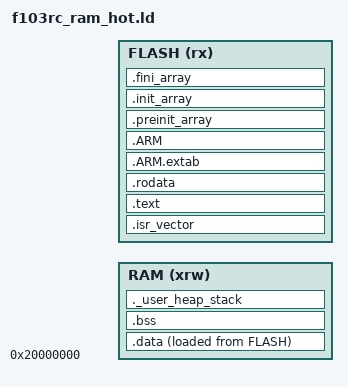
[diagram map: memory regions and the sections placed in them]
/* foc-testbench: copy of the STM32 core 2.12 F103R(C-D-E)T ldscript.ld with the libgcc soft float routines and the SimpleFOC control loop files in RAM (.data). */
/**
 ******************************************************************************
 * @file      LinkerScript.ld
 * @author    Auto-generated by STM32CubeIDE
 * @brief     Linker script for STM32F103C4Tx Device from STM32F1 series
 *                      16Kbytes FLASH
 *                      6Kbytes RAM
 *
 *            Set heap size, stack size and stack location according
 *            to application requirements.
 *
 *            Set memory bank area and size if external memory is used
 ******************************************************************************
 * @attention
 *
 * <h2><center>&copy; Copyright (c) 2020 STMicroelectronics.
 * All rights reserved.</center></h2>
 *
 * This software component is licensed by ST under BSD 3-Clause license,
 * the "License"; You may not use this file except in compliance with the
 * License. You may obtain a copy of the License at:
 *                        opensource.org/licenses/BSD-3-Clause
 *
 ******************************************************************************
 */

/* Entry Point */
ENTRY(Reset_Handler)

/* Highest address of the user mode stack */
_estack = ORIGIN(RAM) + LENGTH(RAM);	/* end of "RAM" Ram type memory */

_Min_Heap_Size = 0x200;	/* required amount of heap  */
_Min_Stack_Size = 0x400;	/* required amount of stack */

/* Memories definition */
MEMORY
{
  RAM    (xrw)    : ORIGIN = 0x20000000,   LENGTH = LD_MAX_DATA_SIZE
  FLASH    (rx)    : ORIGIN = 0x8000000 + LD_FLASH_OFFSET, LENGTH = LD_MAX_SIZE - LD_FLASH_OFFSET
}

/* Sections */
SECTIONS
{
  /* The startup code into "FLASH" Rom type memory */
  .isr_vector :
  {
    . = ALIGN(4);
    KEEP(*(.isr_vector)) /* Startup code */
    . = ALIGN(4);
  } >FLASH

  /* The program code and other data into "FLASH" Rom type memory */
  .text :
  {
    . = ALIGN(4);
    EXCLUDE_FILE(*libgcc.a:_arm_addsubsf3.o *libgcc.a:_arm_mulsf3.o *libgcc.a:_arm_muldivsf3.o *libgcc.a:_arm_cmpsf2.o *libgcc.a:_arm_fixsfsi.o *libgcc.a:_arm_fixunssfsi.o *libgcc.a:_arm_unordsf2.o *FOCMotor.cpp.o *BLDCMotor.cpp.o *pid.cpp.o *lowpass_filter.cpp.o *foc_utils.cpp.o *LowsideCurrentSense.cpp.o *CurrentSense.cpp.o *Sensor.cpp.o *HallSensor.cpp.o *SmoothingSensor.cpp.o *BLDCDriver6PWM.cpp.o *stm32_mcu.cpp.o *stm32f1_mcu.cpp.o *stm32_timerutils.cpp.o *stm32_adc_utils.cpp.o *libm.a:libm_a-ef_fmod.o *libm.a:libm_a-wf_fmod.o) *(.text .text*)   /* code, except the RAM functions below */
    *(.glue_7)         /* glue arm to thumb code */
    *(.glue_7t)        /* glue thumb to arm code */
    *(.eh_frame)

    KEEP (*(.init))
    KEEP (*(.fini))

    . = ALIGN(4);
    _etext = .;        /* define a global symbols at end of code */
  } >FLASH

  /* Constant data into "FLASH" Rom type memory */
  .rodata :
  {
    . = ALIGN(4);
    *(.rodata)         /* .rodata sections (constants, strings, etc.) */
    *(.rodata*)        /* .rodata* sections (constants, strings, etc.) */
    . = ALIGN(4);
  } >FLASH

  .ARM.extab (READONLY) : {
    . = ALIGN(4);
    *(.ARM.extab* .gnu.linkonce.armextab.*)
    . = ALIGN(4);
  } >FLASH

  .ARM (READONLY) : {
    . = ALIGN(4);
    __exidx_start = .;
    *(.ARM.exidx*)
    __exidx_end = .;
    . = ALIGN(4);
  } >FLASH

  .preinit_array (READONLY) :
  {
    . = ALIGN(4);
    PROVIDE_HIDDEN (__preinit_array_start = .);
    KEEP (*(.preinit_array*))
    PROVIDE_HIDDEN (__preinit_array_end = .);
    . = ALIGN(4);
  } >FLASH

  .init_array (READONLY) :
  {
    . = ALIGN(4);
    PROVIDE_HIDDEN (__init_array_start = .);
    KEEP (*(SORT(.init_array.*)))
    KEEP (*(.init_array*))
    PROVIDE_HIDDEN (__init_array_end = .);
    . = ALIGN(4);
  } >FLASH

  .fini_array (READONLY) :
  {
    . = ALIGN(4);
    PROVIDE_HIDDEN (__fini_array_start = .);
    KEEP (*(SORT(.fini_array.*)))
    KEEP (*(.fini_array*))
    PROVIDE_HIDDEN (__fini_array_end = .);
    . = ALIGN(4);
  } >FLASH

  /* Used by the startup to initialize data */
  _sidata = LOADADDR(.data);

  /* Initialized data sections into "RAM" Ram type memory */
  .data :
  {
    . = ALIGN(4);
    _sdata = .;        /* create a global symbol at data start */
    *(.data)           /* .data sections */
    *(.data*)          /* .data* sections */
    *(.RamFunc)        /* .RamFunc sections */
    *(.RamFunc*)       /* .RamFunc* sections */
    /* bench: the libgcc soft float routines and the SimpleFOC control loop files run from RAM (no flash wait states), copied by the startup with .data */
    . = ALIGN(4);
    *libgcc.a:_arm_addsubsf3.o(.text .text*) *libgcc.a:_arm_mulsf3.o(.text .text*) *libgcc.a:_arm_muldivsf3.o(.text .text*) *libgcc.a:_arm_cmpsf2.o(.text .text*) *libgcc.a:_arm_fixsfsi.o(.text .text*) *libgcc.a:_arm_fixunssfsi.o(.text .text*) *libgcc.a:_arm_unordsf2.o(.text .text*) *FOCMotor.cpp.o(.text .text*) *BLDCMotor.cpp.o(.text .text*) *pid.cpp.o(.text .text*) *lowpass_filter.cpp.o(.text .text*) *foc_utils.cpp.o(.text .text*) *LowsideCurrentSense.cpp.o(.text .text*) *CurrentSense.cpp.o(.text .text*) *Sensor.cpp.o(.text .text*) *HallSensor.cpp.o(.text .text*) *SmoothingSensor.cpp.o(.text .text*) *BLDCDriver6PWM.cpp.o(.text .text*) *stm32_mcu.cpp.o(.text .text*) *stm32f1_mcu.cpp.o(.text .text*) *stm32_timerutils.cpp.o(.text .text*) *stm32_adc_utils.cpp.o(.text .text*) *libm.a:libm_a-ef_fmod.o(.text .text*) *libm.a:libm_a-wf_fmod.o(.text .text*)

    . = ALIGN(4);
    _edata = .;        /* define a global symbol at data end */

  } >RAM AT> FLASH

  /* Uninitialized data section into "RAM" Ram type memory */
  . = ALIGN(4);
  .bss :
  {
    /* This is used by the startup in order to initialize the .bss section */
    _sbss = .;         /* define a global symbol at bss start */
    __bss_start__ = _sbss;
    *(.bss)
    *(.bss*)
    *(COMMON)

    . = ALIGN(4);
    _ebss = .;         /* define a global symbol at bss end */
    __bss_end__ = _ebss;
  } >RAM

  /* User_heap_stack section, used to check that there is enough "RAM" Ram  type memory left */
  ._user_heap_stack :
  {
    . = ALIGN(8);
    PROVIDE ( end = . );
    PROVIDE ( _end = . );
    . = . + _Min_Heap_Size;
    . = . + _Min_Stack_Size;
    . = ALIGN(8);
  } >RAM

  /* Remove information from the compiler libraries */
  /DISCARD/ :
  {
    libc.a ( * )
    libm.a ( * )
    libgcc.a ( * )
  }

  .ARM.attributes 0 : { *(.ARM.attributes) }
}
